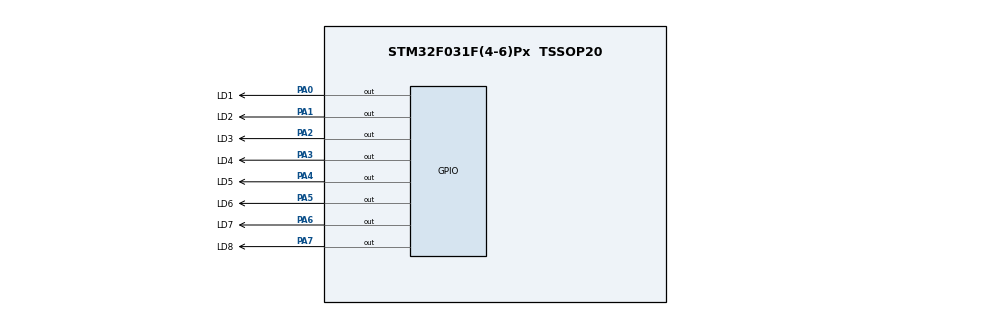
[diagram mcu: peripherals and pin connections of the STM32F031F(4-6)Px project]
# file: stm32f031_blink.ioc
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Mcu.Family=STM32F0
Mcu.Name=STM32F031F(4-6)Px
Mcu.Package=TSSOP20
PA0.GPIO_Label=LD1
PA0.Signal=GPIO_Output
PA1.GPIO_Label=LD2
PA1.Signal=GPIO_Output
PA13.Mode=Serial_Wire
PA13.Signal=SYS_SWDIO
PA14.Mode=Serial_Wire
PA14.Signal=SYS_SWCLK
PA2.GPIO_Label=LD3
PA2.Signal=GPIO_Output
PA3.GPIO_Label=LD4
PA3.Signal=GPIO_Output
PA4.GPIO_Label=LD5
PA4.Signal=GPIO_Output
PA5.GPIO_Label=LD6
PA5.Signal=GPIO_Output
PA6.GPIO_Label=LD7
PA6.Signal=GPIO_Output
PA7.GPIO_Label=LD8
PA7.Signal=GPIO_Output
ProjectManager.HeapSize=0x200
ProjectManager.StackSize=0x400
ProjectManager.TargetToolchain=STM32CubeIDE
board=custom

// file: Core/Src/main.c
/* USER CODE BEGIN Header */
/**
  ******************************************************************************
  * @file           : main.c
  * @brief          : Main program body
  ******************************************************************************
  * @attention
  *
  * <h2><center>&copy; Copyright (c) 2020 STMicroelectronics.
  * All rights reserved.</center></h2>
  *
  * This software component is licensed by ST under BSD 3-Clause license,
  * the "License"; You may not use this file except in compliance with the
  * License. You may obtain a copy of the License at:
  *                        opensource.org/licenses/BSD-3-Clause
  *
  ******************************************************************************
  */
/* USER CODE END Header */

#include "main.h"

void SystemClock_Config(void);
static void MX_GPIO_Init(void);

int main(void)
{
  /* USER CODE BEGIN 1 */
#define LEDS 8
int8_t count;
  /* USER CODE END 1 */

  /* MCU Configuration--------------------------------------------------------*/

  /* Reset of all peripherals, Initializes the Flash interface and the Systick. */
  HAL_Init();

  /* Configure the system clock */
  SystemClock_Config();

  /* Initialize all configured peripherals */
  MX_GPIO_Init();

  /* Infinite loop */
  /* USER CODE BEGIN WHILE */
  while (1)
  {
	  for ( count = 0; count < LEDS; count++ ) {
		  HAL_GPIO_WritePin(LD1_GPIO_Port, 1 << count, GPIO_PIN_SET);
		  HAL_Delay(100);
		  if ( count > 0 ) HAL_GPIO_WritePin(LD1_GPIO_Port, 1 << count-1, GPIO_PIN_RESET);
	  }
	  HAL_Delay(100);
	  for ( count = LEDS-1; count >=0 ; count-- ) {
		  HAL_GPIO_WritePin(LD1_GPIO_Port, 1 << count, GPIO_PIN_SET);
		  HAL_Delay(100);
		  if ( count < LEDS-1 ) HAL_GPIO_WritePin(LD1_GPIO_Port, 1 << count+1, GPIO_PIN_RESET);
	  }
	  HAL_Delay(100);
    /* USER CODE END WHILE */

  }
}

void SystemClock_Config(void)
{
  RCC_OscInitTypeDef RCC_OscInitStruct = {0};
  RCC_ClkInitTypeDef RCC_ClkInitStruct = {0};

  /** Initializes the CPU, AHB and APB busses clocks
  */
  RCC_OscInitStruct.OscillatorType = RCC_OSCILLATORTYPE_HSI;
  RCC_OscInitStruct.HSIState = RCC_HSI_ON;
  RCC_OscInitStruct.HSICalibrationValue = RCC_HSICALIBRATION_DEFAULT;
  RCC_OscInitStruct.PLL.PLLState = RCC_PLL_NONE;
  if (HAL_RCC_OscConfig(&RCC_OscInitStruct) != HAL_OK)
  {
    Error_Handler();
  }
  /** Initializes the CPU, AHB and APB busses clocks
  */
  RCC_ClkInitStruct.ClockType = RCC_CLOCKTYPE_HCLK|RCC_CLOCKTYPE_SYSCLK
                              |RCC_CLOCKTYPE_PCLK1;
  RCC_ClkInitStruct.SYSCLKSource = RCC_SYSCLKSOURCE_HSI;
  RCC_ClkInitStruct.AHBCLKDivider = RCC_SYSCLK_DIV1;
  RCC_ClkInitStruct.APB1CLKDivider = RCC_HCLK_DIV1;

  if (HAL_RCC_ClockConfig(&RCC_ClkInitStruct, FLASH_LATENCY_0) != HAL_OK)
  {
    Error_Handler();
  }
}

static void MX_GPIO_Init(void)
{
  GPIO_InitTypeDef GPIO_InitStruct = {0};

  /* GPIO Ports Clock Enable */
  __HAL_RCC_GPIOA_CLK_ENABLE();

  /*Configure GPIO pin Output Level */
  HAL_GPIO_WritePin(GPIOA, LD1_Pin|LD2_Pin|LD3_Pin|LD4_Pin
                          |LD5_Pin|LD6_Pin|LD7_Pin|LD8_Pin, GPIO_PIN_RESET);

  /*Configure GPIO pins : LD1_Pin LD2_Pin LD3_Pin LD4_Pin
                           LD5_Pin LD6_Pin LD7_Pin LD8_Pin */
  GPIO_InitStruct.Pin = LD1_Pin|LD2_Pin|LD3_Pin|LD4_Pin
                          |LD5_Pin|LD6_Pin|LD7_Pin|LD8_Pin;
  GPIO_InitStruct.Mode = GPIO_MODE_OUTPUT_PP;
  GPIO_InitStruct.Pull = GPIO_NOPULL;
  GPIO_InitStruct.Speed = GPIO_SPEED_FREQ_LOW;
  HAL_GPIO_Init(GPIOA, &GPIO_InitStruct);

}

void Error_Handler(void)
{
}

/************************ (C) COPYRIGHT STMicroelectronics *****END OF FILE****/
